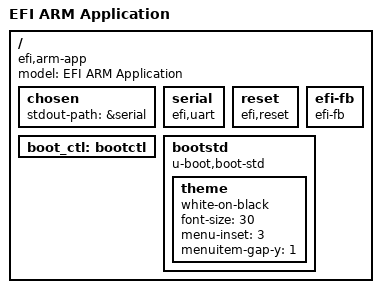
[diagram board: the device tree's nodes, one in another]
// SPDX-License-Identifier: GPL-2.0+
/*
 * Copyright (c) 2015 Google, Inc
 */

/dts-v1/;

/include/ "skeleton.dtsi"

/ {
	model = "EFI ARM Application";
	compatible = "efi,arm-app";

	chosen {
		stdout-path = &serial;
	};

	serial: serial {
		compatible = "efi,uart";
	};

	reset {
		compatible = "efi,reset";
		bootph-all;
	};
	efi-fb {
		compatible = "efi-fb";
		bootph-some-ram;
	};


	boot_ctl: bootctl {
	};

	bootstd {
		compatible = "u-boot,boot-std";
		theme {
			white-on-black;
			font-size = <30>;
			menu-inset = <3>;
			menuitem-gap-y = <1>;
		};
	};

};

#include "bootctl.dtsi"
